# AE822FA0E5597BS0_CM55_HP_View register map
Vendor: Alif Semiconductor; Series: E8; File version: 1.0
CPU: CM55 r1p0, selectable endian, MPU, FPU, double-precision FPU, DSP, VTOR, 8 interrupt priority bits, 1 SAU regions
Registers are 32-bit, read-write, reset 0x0 unless marked. A register's access mark holds for its fields unless they carry their own. Offsets are from the block's base; [hi:lo] are bit positions; lines under a group give offsets from that group; {n}, {i} and the like mark numbered series.

## PINMUX
Base 0x1A603000
{0x0+0x20*i} PINMUX_CFG[{i}] (i=0..17) group
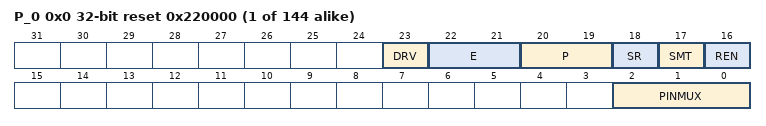
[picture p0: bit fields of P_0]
  {0x0+4j} P_{j} reset 0x220000 (j=0..7) — Control Register for Port n, Pin {j}
    [23] DRV — Driver type
      0=Push-pull; 1=Open drain
    [22:21] E — Output drive strength NOTE: Reset value is 0x3 (12 mA) for registers P4_4, P4_5, P4_6, P4_7
      0=2 mA; 1=4 mA; 2=8 mA; 3=12 mA
    [20:19] P — Driver disabled state control
      0=High-Z; 1=Pull-up; 2=Pull-down; 3=Bus keeper
    [18] SR — Slew rate
      0=Slow; 1=Fast
    [17] SMT — Schmitt trigger (hysteresis) enable
      0=No hysteresis; 1=Hysteresis enabled
    [16] REN — Receiver enable NOTE: Reset value is 0x1 for registers P4_4, P4_5, P4_6, P4_7
      0=Receiver disabled, pin reads return 0; 1=Receiver enabled
    [2:0] PINMUX — Pin multiplexing control field 0x1-0xN: Selects other peripherals as shown in table Pin Function Multiplexing of the device series-specific Datasheet. Un-mapped: Select GPIOn_{j} NOTE: Reset value is 0x1 for registers P4_4, P4_5, P4_6, P4_7
      0=Selects GPIOn_{j} signal from GPIOn peripheral

## STOP_MODE
Base 0x1A60F000
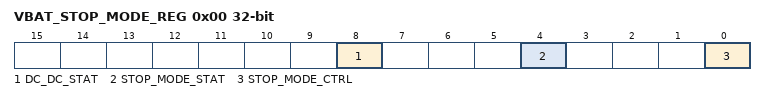
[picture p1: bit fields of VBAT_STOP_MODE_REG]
0x00 VBAT_STOP_MODE_REG — VBAT Stop Mode Control and Status Register
  [8] DC_DC_STAT ro — DC-DC Status Reflects the real-time status of DC-DC power
    0=DC-DC is ON; 1=DC-DC is OFF
  [4] STOP_MODE_STAT write-1-clears — Stop Mode Status - HW sets this bit when DC-DC was turned off - SW clears this bit by writing 0x1
  [0] STOP_MODE_CTRL — Stop Mode Control - SW sets this bit to enter stop mode - HW clears this bit when there is a wake-up event

## EVTRTR1
Base 0x400E2000
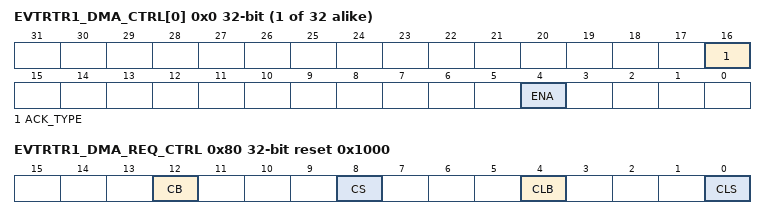
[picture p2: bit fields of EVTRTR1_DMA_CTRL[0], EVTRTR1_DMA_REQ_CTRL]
{0x0+4i} EVTRTR1_DMA_CTRL[{i}] (i=0..31) — DMA/Event Router Control and Status Register (n)
  [16] ACK_TYPE ro — DMA handshake type status for DMA peripheral
    0=Peripheral completes the REQ-ACK handshake with DMA controller. Event Router passing through REQ-ACK between DMA controller and peripheral.; 1=Event Router completes the REQ-ACK handshake with DMA controller. Peripheral raises DMA request without responding to ACK from DMA controller.
  [4] ENA — DMA channel enable
    0=Disable DMA channel; 1=Enable DMA channel
0x80 EVTRTR1_DMA_REQ_CTRL reset 0x1000 — DMA Request Control Register
  [all] fields
    0=Disable; 1=Enable
  [12] CB — Enable DMA request on DMACBREQ (DMAC Burst Request) Note: It is recommended to enable all DMA requests on the burst request line (DMACBREQ). For single transfer, the number of beats in a burst should be set to 1 (DMA_CCRn[SRC_BURST_LEN] = 0x0).
  [8] CS — Enable DMA request on DMACSREQ (DMAC Single Request) Note: It is recommended to enable all DMA requests on the burst request line (DMACBREQ), even for single transfer.
  [4] CLB — Enable DMA request on DMACLBREQ (DMAC Last Burst Request) Note: Do not use. The current implementation does not support transfers from a peripheral with an unspecified length ('peripheral length management').
  [0] CLS — Enable DMA request on DMACLSREQ (DMAC Last Single Request) Note: Do not use. The current implementation does not support transfers from a peripheral with an unspecified length ('peripheral length management').
0x90 EVTRTR1_DMA_ACK_TYPE0 reset 0xFF0000 — DMA Handshake Type Register 0
  [31:0] ACK — Select DMA handshake type for DMA group #0

## M55HP_CFG
Base 0x400F0000
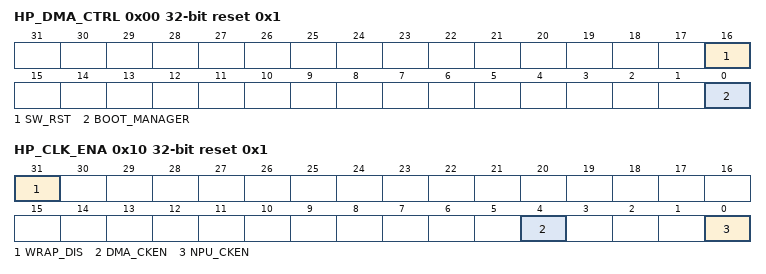
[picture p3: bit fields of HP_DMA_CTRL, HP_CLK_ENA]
0x00 HP_DMA_CTRL reset 0x1 — DMA1 Boot Control Register
  [16] SW_RST wo — Software reset for DMA1
    0=No reset; 1=Reset DMA1. This bit is self-cleared.
  [0] BOOT_MANAGER — When DMA1 exits from reset, this bit controls the security state of the DMA manager thread
    0=Assigns DMA manager to the secure state; 1=Assigns DMA manager to the non-secure state
0x04 HP_DMA_IRQ reset 0xFFFFFFFF — DMA1 Boot IRQ Non-Secure Register
  [31:0] BOOT_IRQ — Controls the security state of an event-interrupt resource, when DMA1 exits from reset
    0=DMA1 assigns event x or IRQ[x] to the secure state; 1=DMA1 assigns event x or IRQ[x] to the non-secure state
0x08 HP_DMA_PERIPH reset 0xFFFFFFFF — DMA1 Boot Peripheral Non-Secure Register
  [31:0] BOOT_PERIPH — Controls the security state of a peripheral request interface, when DMA1 exits from reset
    0=DMA1 assigns peripheral request interface x to the secure state; 1=DMA1 assigns peripheral request interface x to the non-secure state
0x0C HP_DMA_SEL — DMA1 Select Register
  [31:24] FLT_ENA — This field provides glitch filtering for the GPIO9_[7-0] signals that are mapped to DMA1 inputs [31-24] DMA1 (M55-HP) Requests Mapping). For each bit:
    0=Disable glitch-filter for GPIO input; 1=Enable glitch-filter for GPIO input
0x10 HP_CLK_ENA reset 0x1 — Peripheral Clock Enable Register
  [31] WRAP_DIS — Enable wrap cleaner
    0=Enable wrap cleaner; 1=Disable wrap cleaner
  [4] DMA_CKEN — Enable clock for DMA1 and EVTRTR1
    0=Disable clock; 1=Enable clock
  [0] NPU_CKEN — Enable clock for NPU-HP Note: When this bit is 0x1, the clock is automatically controlled. When this bit is 0x0, the clock is forcibly disabled, overriding the automatic control. Forcing this clock off can block RTSS-HP power domain state transitions or resets and does not save more power than the automatic gating. Therefore, this bit should remain 0x1 in normal operation. The control exists for test and debug purposes only.
    0=Disable clock; 1=Enable clock (automatic gating)
